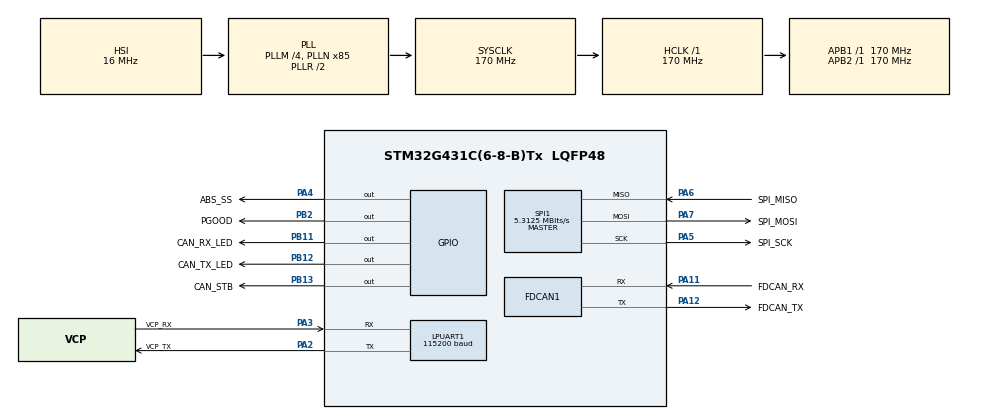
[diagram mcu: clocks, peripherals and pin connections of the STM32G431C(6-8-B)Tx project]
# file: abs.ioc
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Dma.LPUART1_TX.0.Direction=DMA_MEMORY_TO_PERIPH
Dma.LPUART1_TX.0.EventEnable=DISABLE
Dma.LPUART1_TX.0.Instance=DMA1_Channel1
Dma.LPUART1_TX.0.MemDataAlignment=DMA_MDATAALIGN_BYTE
Dma.LPUART1_TX.0.MemInc=DMA_MINC_ENABLE
Dma.LPUART1_TX.0.Mode=DMA_NORMAL
Dma.LPUART1_TX.0.PeriphDataAlignment=DMA_PDATAALIGN_BYTE
Dma.LPUART1_TX.0.PeriphInc=DMA_PINC_DISABLE
Dma.LPUART1_TX.0.Polarity=HAL_DMAMUX_REQ_GEN_RISING
Dma.LPUART1_TX.0.Priority=DMA_PRIORITY_LOW
Dma.LPUART1_TX.0.RequestNumber=1
Dma.LPUART1_TX.0.SignalID=NONE
Dma.LPUART1_TX.0.SyncEnable=DISABLE
Dma.LPUART1_TX.0.SyncPolarity=HAL_DMAMUX_SYNC_NO_EVENT
Dma.LPUART1_TX.0.SyncRequestNumber=1
Dma.LPUART1_TX.0.SyncSignalID=NONE
Dma.Request0=LPUART1_TX
Dma.Request1=SPI1_RX
Dma.Request2=SPI1_TX
Dma.SPI1_RX.1.Direction=DMA_PERIPH_TO_MEMORY
Dma.SPI1_RX.1.EventEnable=DISABLE
Dma.SPI1_RX.1.Instance=DMA1_Channel2
Dma.SPI1_RX.1.MemDataAlignment=DMA_MDATAALIGN_HALFWORD
Dma.SPI1_RX.1.MemInc=DMA_MINC_ENABLE
Dma.SPI1_RX.1.Mode=DMA_NORMAL
Dma.SPI1_RX.1.PeriphDataAlignment=DMA_PDATAALIGN_HALFWORD
Dma.SPI1_RX.1.PeriphInc=DMA_PINC_DISABLE
Dma.SPI1_RX.1.Polarity=HAL_DMAMUX_REQ_GEN_RISING
Dma.SPI1_RX.1.Priority=DMA_PRIORITY_LOW
Dma.SPI1_RX.1.RequestNumber=1
Dma.SPI1_RX.1.SignalID=NONE
Dma.SPI1_RX.1.SyncEnable=DISABLE
Dma.SPI1_RX.1.SyncPolarity=HAL_DMAMUX_SYNC_NO_EVENT
Dma.SPI1_RX.1.SyncRequestNumber=1
Dma.SPI1_RX.1.SyncSignalID=NONE
Dma.SPI1_TX.2.Direction=DMA_MEMORY_TO_PERIPH
Dma.SPI1_TX.2.EventEnable=DISABLE
Dma.SPI1_TX.2.Instance=DMA1_Channel3
Dma.SPI1_TX.2.MemDataAlignment=DMA_MDATAALIGN_HALFWORD
Dma.SPI1_TX.2.MemInc=DMA_MINC_ENABLE
Dma.SPI1_TX.2.Mode=DMA_NORMAL
Dma.SPI1_TX.2.PeriphDataAlignment=DMA_PDATAALIGN_HALFWORD
Dma.SPI1_TX.2.PeriphInc=DMA_PINC_DISABLE
Dma.SPI1_TX.2.Polarity=HAL_DMAMUX_REQ_GEN_RISING
Dma.SPI1_TX.2.Priority=DMA_PRIORITY_LOW
Dma.SPI1_TX.2.RequestNumber=1
Dma.SPI1_TX.2.SignalID=NONE
Dma.SPI1_TX.2.SyncEnable=DISABLE
Dma.SPI1_TX.2.SyncPolarity=HAL_DMAMUX_SYNC_NO_EVENT
Dma.SPI1_TX.2.SyncRequestNumber=1
Dma.SPI1_TX.2.SyncSignalID=NONE
FDCAN1.AutoRetransmission=ENABLE
FDCAN1.CalculateBaudRateNominal=999999
FDCAN1.CalculateTimeBitNominal=1000
FDCAN1.CalculateTimeQuantumNominal=11.764705882352942
FDCAN1.ClockDivider=FDCAN_CLOCK_DIV2
FDCAN1.DataSyncJumpWidth=5
FDCAN1.DataTimeSeg1=11
FDCAN1.DataTimeSeg2=5
FDCAN1.ExtFiltersNbr=3
FDCAN1.FrameFormat=FDCAN_FRAME_FD_BRS
FDCAN1.NominalPrescaler=1
FDCAN1.NominalSyncJumpWidth=16
FDCAN1.NominalTimeSeg1=56
FDCAN1.NominalTimeSeg2=28
LPUART1.BaudRate=115200
Mcu.Family=STM32G4
Mcu.Name=STM32G431C(6-8-B)Tx
Mcu.Package=LQFP48
NVIC.DMA1_Channel1_IRQn=true\:0\:0\:false\:false\:true\:false\:true\:true
NVIC.DMA1_Channel2_IRQn=true\:0\:0\:false\:false\:true\:false\:true\:true
NVIC.DMA1_Channel3_IRQn=true\:0\:0\:false\:false\:true\:false\:true\:true
NVIC.FDCAN1_IT0_IRQn=true\:0\:0\:false\:false\:true\:true\:true\:true
NVIC.FDCAN1_IT1_IRQn=true\:0\:0\:false\:false\:true\:true\:true\:true
NVIC.LPUART1_IRQn=true\:0\:0\:false\:false\:true\:true\:true\:true
NVIC.PriorityGroup=NVIC_PRIORITYGROUP_4
NVIC.SPI1_IRQn=true\:0\:0\:false\:false\:true\:true\:true\:true
NVIC.TIM1_TRG_COM_TIM17_IRQn=true\:0\:0\:false\:false\:true\:true\:true\:true
NVIC.TIM1_UP_TIM16_IRQn=true\:0\:0\:false\:false\:true\:true\:true\:true
PA11.GPIO_Label=FDCAN_RX
PA11.Mode=FDCAN_Activate
PA11.Signal=FDCAN1_RX
PA12.GPIO_Label=FDCAN_TX
PA12.Mode=FDCAN_Activate
PA12.Signal=FDCAN1_TX
PA13.GPIO_Label=SWDIO
PA13.Mode=Trace_Asynchronous_SW
PA13.Signal=SYS_JTMS-SWDIO
PA14.GPIO_Label=SWCLK
PA14.Mode=Trace_Asynchronous_SW
PA14.Signal=SYS_JTCK-SWCLK
PA2.GPIO_Label=VCP_TX
PA2.Mode=Asynchronous
PA2.Signal=LPUART1_TX
PA3.GPIO_Label=VCP_RX
PA3.Mode=Asynchronous
PA3.Signal=LPUART1_RX
PA4.GPIO_Label=ABS_SS
PA4.Signal=GPIO_Output
PA5.GPIO_Label=SPI_SCK
PA5.Mode=Full_Duplex_Master
PA5.Signal=SPI1_SCK
PA6.GPIO_Label=SPI_MISO
PA6.Mode=Full_Duplex_Master
PA6.Signal=SPI1_MISO
PA7.GPIO_Label=SPI_MOSI
PA7.Mode=Full_Duplex_Master
PA7.Signal=SPI1_MOSI
PB11.GPIO_Label=CAN_RX_LED
PB11.Signal=GPIO_Output
PB12.GPIO_Label=CAN_TX_LED
PB12.Signal=GPIO_Output
PB13.GPIO_Label=CAN_STB
PB13.Signal=GPIO_Output
PB2.GPIO_Label=PGOOD
PB2.Signal=GPIO_Output
PB3.GPIO_Label=SWO
PB3.Mode=Trace_Asynchronous_SW
PB3.Signal=SYS_JTDO-SWO
ProjectManager.HeapSize=0x200
ProjectManager.StackSize=0x400
ProjectManager.TargetToolchain=CMake
RCC.ADC12Freq_Value=170000000
RCC.AHBFreq_Value=170000000
RCC.APB1Freq_Value=170000000
RCC.APB1TimFreq_Value=170000000
RCC.APB2Freq_Value=170000000
RCC.APB2TimFreq_Value=170000000
RCC.CortexFreq_Value=170000000
RCC.EXTERNAL_CLOCK_VALUE=12288000
RCC.HCLKFreq_Value=170000000
RCC.HSE_VALUE=8000000
RCC.HSI48_VALUE=48000000
RCC.HSI_VALUE=16000000
RCC.LSE_VALUE=32768
RCC.PLLM=RCC_PLLM_DIV4
RCC.PLLN=85
RCC.SYSCLKFreq_VALUE=170000000
RCC.SYSCLKSource=RCC_SYSCLKSOURCE_PLLCLK
RCC.USBFreq_Value=170000000
RCC.VCOOutputFreq_Value=340000000
SPI1.BaudRatePrescaler=SPI_BAUDRATEPRESCALER_32
SPI1.CLKPhase=SPI_PHASE_2EDGE
SPI1.CRCCalculation=SPI_CRCCALCULATION_DISABLE
SPI1.CalculateBaudRate=5.3125 MBits/s
SPI1.DataSize=SPI_DATASIZE_16BIT
SPI1.Direction=SPI_DIRECTION_2LINES
SPI1.Mode=SPI_MODE_MASTER
SPI1.VirtualType=VM_MASTER
TIM16.PeriodNoDither=3333
TIM16.Prescaler=1699
TIM17.PeriodNoDither=3333
TIM17.Prescaler=1699
VP_SYS_VS_DBSignals.Mode=DisableDeadBatterySignals
VP_TIM16_VS_ClockSourceINT.Mode=Enable_Timer
VP_TIM17_VS_ClockSourceINT.Mode=Enable_Timer
board=custom

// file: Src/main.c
/* USER CODE BEGIN Header */
/**
  ******************************************************************************
  * @file           : main.c
  * @brief          : Main program body
  ******************************************************************************
  * @attention
  *
  * Copyright (c) 2026 STMicroelectronics.
  * All rights reserved.
  *
  * This software is licensed under terms that can be found in the LICENSE file
  * in the root directory of this software component.
  * If no LICENSE file comes with this software, it is provided AS-IS.
  *
  ******************************************************************************
  */
/* USER CODE END Header */
#include "main.h"

FDCAN_HandleTypeDef hfdcan1;

UART_HandleTypeDef hlpuart1;
DMA_HandleTypeDef hdma_lpuart1_tx;

SPI_HandleTypeDef hspi1;
DMA_HandleTypeDef hdma_spi1_rx;
DMA_HandleTypeDef hdma_spi1_tx;

TIM_HandleTypeDef htim16;
TIM_HandleTypeDef htim17;

void SystemClock_Config(void);
static void MX_GPIO_Init(void);
static void MX_DMA_Init(void);
static void MX_LPUART1_UART_Init(void);
static void MX_FDCAN1_Init(void);
static void MX_SPI1_Init(void);
static void MX_TIM16_Init(void);
static void MX_TIM17_Init(void);

int main(void)
{

  /* MCU Configuration--------------------------------------------------------*/

  /* Reset of all peripherals, Initializes the Flash interface and the Systick. */
  HAL_Init();

  /* Configure the system clock */
  SystemClock_Config();

  /* Initialize all configured peripherals */
  MX_GPIO_Init();
  MX_DMA_Init();
  MX_LPUART1_UART_Init();
  MX_FDCAN1_Init();
  MX_SPI1_Init();
  MX_TIM16_Init();
  MX_TIM17_Init();
  /* USER CODE BEGIN 2 */
  Init();
  /* USER CODE END 2 */

  /* Infinite loop */
  /* USER CODE BEGIN WHILE */
  Loop();
    /* USER CODE END WHILE */

}

void SystemClock_Config(void)
{
  RCC_OscInitTypeDef RCC_OscInitStruct = {0};
  RCC_ClkInitTypeDef RCC_ClkInitStruct = {0};

  /** Configure the main internal regulator output voltage
  */
  HAL_PWREx_ControlVoltageScaling(PWR_REGULATOR_VOLTAGE_SCALE1_BOOST);

  /** Initializes the RCC Oscillators according to the specified parameters
  * in the RCC_OscInitTypeDef structure.
  */
  RCC_OscInitStruct.OscillatorType = RCC_OSCILLATORTYPE_HSI;
  RCC_OscInitStruct.HSIState = RCC_HSI_ON;
  RCC_OscInitStruct.HSICalibrationValue = RCC_HSICALIBRATION_DEFAULT;
  RCC_OscInitStruct.PLL.PLLState = RCC_PLL_ON;
  RCC_OscInitStruct.PLL.PLLSource = RCC_PLLSOURCE_HSI;
  RCC_OscInitStruct.PLL.PLLM = RCC_PLLM_DIV4;
  RCC_OscInitStruct.PLL.PLLN = 85;
  RCC_OscInitStruct.PLL.PLLP = RCC_PLLP_DIV2;
  RCC_OscInitStruct.PLL.PLLQ = RCC_PLLQ_DIV2;
  RCC_OscInitStruct.PLL.PLLR = RCC_PLLR_DIV2;
  if (HAL_RCC_OscConfig(&RCC_OscInitStruct) != HAL_OK)
  {
    Error_Handler();
  }

  /** Initializes the CPU, AHB and APB buses clocks
  */
  RCC_ClkInitStruct.ClockType = RCC_CLOCKTYPE_HCLK|RCC_CLOCKTYPE_SYSCLK
                              |RCC_CLOCKTYPE_PCLK1|RCC_CLOCKTYPE_PCLK2;
  RCC_ClkInitStruct.SYSCLKSource = RCC_SYSCLKSOURCE_PLLCLK;
  RCC_ClkInitStruct.AHBCLKDivider = RCC_SYSCLK_DIV1;
  RCC_ClkInitStruct.APB1CLKDivider = RCC_HCLK_DIV1;
  RCC_ClkInitStruct.APB2CLKDivider = RCC_HCLK_DIV1;

  if (HAL_RCC_ClockConfig(&RCC_ClkInitStruct, FLASH_LATENCY_4) != HAL_OK)
  {
    Error_Handler();
  }
}

static void MX_FDCAN1_Init(void)
{

  hfdcan1.Instance = FDCAN1;
  hfdcan1.Init.ClockDivider = FDCAN_CLOCK_DIV2;
  hfdcan1.Init.FrameFormat = FDCAN_FRAME_FD_BRS;
  hfdcan1.Init.Mode = FDCAN_MODE_NORMAL;
  hfdcan1.Init.AutoRetransmission = ENABLE;
  hfdcan1.Init.TransmitPause = DISABLE;
  hfdcan1.Init.ProtocolException = DISABLE;
  hfdcan1.Init.NominalPrescaler = 1;
  hfdcan1.Init.NominalSyncJumpWidth = 16;
  hfdcan1.Init.NominalTimeSeg1 = 56;
  hfdcan1.Init.NominalTimeSeg2 = 28;
  hfdcan1.Init.DataPrescaler = 1;
  hfdcan1.Init.DataSyncJumpWidth = 5;
  hfdcan1.Init.DataTimeSeg1 = 11;
  hfdcan1.Init.DataTimeSeg2 = 5;
  hfdcan1.Init.StdFiltersNbr = 0;
  hfdcan1.Init.ExtFiltersNbr = 3;
  hfdcan1.Init.TxFifoQueueMode = FDCAN_TX_FIFO_OPERATION;
  if (HAL_FDCAN_Init(&hfdcan1) != HAL_OK)
  {
    Error_Handler();
  }

}

static void MX_LPUART1_UART_Init(void)
{

  hlpuart1.Instance = LPUART1;
  hlpuart1.Init.BaudRate = 115200;
  hlpuart1.Init.WordLength = UART_WORDLENGTH_8B;
  hlpuart1.Init.StopBits = UART_STOPBITS_1;
  hlpuart1.Init.Parity = UART_PARITY_NONE;
  hlpuart1.Init.Mode = UART_MODE_TX_RX;
  hlpuart1.Init.HwFlowCtl = UART_HWCONTROL_NONE;
  hlpuart1.Init.OneBitSampling = UART_ONE_BIT_SAMPLE_DISABLE;
  hlpuart1.Init.ClockPrescaler = UART_PRESCALER_DIV1;
  hlpuart1.AdvancedInit.AdvFeatureInit = UART_ADVFEATURE_NO_INIT;
  if (HAL_UART_Init(&hlpuart1) != HAL_OK)
  {
    Error_Handler();
  }
  if (HAL_UARTEx_SetTxFifoThreshold(&hlpuart1, UART_TXFIFO_THRESHOLD_1_8) != HAL_OK)
  {
    Error_Handler();
  }
  if (HAL_UARTEx_SetRxFifoThreshold(&hlpuart1, UART_RXFIFO_THRESHOLD_1_8) != HAL_OK)
  {
    Error_Handler();
  }
  if (HAL_UARTEx_DisableFifoMode(&hlpuart1) != HAL_OK)
  {
    Error_Handler();
  }

}

static void MX_SPI1_Init(void)
{

  /* SPI1 parameter configuration*/
  hspi1.Instance = SPI1;
  hspi1.Init.Mode = SPI_MODE_MASTER;
  hspi1.Init.Direction = SPI_DIRECTION_2LINES;
  hspi1.Init.DataSize = SPI_DATASIZE_16BIT;
  hspi1.Init.CLKPolarity = SPI_POLARITY_LOW;
  hspi1.Init.CLKPhase = SPI_PHASE_2EDGE;
  hspi1.Init.NSS = SPI_NSS_SOFT;
  hspi1.Init.BaudRatePrescaler = SPI_BAUDRATEPRESCALER_32;
  hspi1.Init.FirstBit = SPI_FIRSTBIT_MSB;
  hspi1.Init.TIMode = SPI_TIMODE_DISABLE;
  hspi1.Init.CRCCalculation = SPI_CRCCALCULATION_DISABLE;
  hspi1.Init.CRCPolynomial = 7;
  hspi1.Init.CRCLength = SPI_CRC_LENGTH_DATASIZE;
  hspi1.Init.NSSPMode = SPI_NSS_PULSE_DISABLE;
  if (HAL_SPI_Init(&hspi1) != HAL_OK)
  {
    Error_Handler();
  }

}

static void MX_TIM16_Init(void)
{

  htim16.Instance = TIM16;
  htim16.Init.Prescaler = 1699;
  htim16.Init.CounterMode = TIM_COUNTERMODE_UP;
  htim16.Init.Period = 3333;
  htim16.Init.ClockDivision = TIM_CLOCKDIVISION_DIV1;
  htim16.Init.RepetitionCounter = 0;
  htim16.Init.AutoReloadPreload = TIM_AUTORELOAD_PRELOAD_DISABLE;
  if (HAL_TIM_Base_Init(&htim16) != HAL_OK)
  {
    Error_Handler();
  }

}

static void MX_TIM17_Init(void)
{

  htim17.Instance = TIM17;
  htim17.Init.Prescaler = 1699;
  htim17.Init.CounterMode = TIM_COUNTERMODE_UP;
  htim17.Init.Period = 3333;
  htim17.Init.ClockDivision = TIM_CLOCKDIVISION_DIV1;
  htim17.Init.RepetitionCounter = 0;
  htim17.Init.AutoReloadPreload = TIM_AUTORELOAD_PRELOAD_DISABLE;
  if (HAL_TIM_Base_Init(&htim17) != HAL_OK)
  {
    Error_Handler();
  }

}

static void MX_DMA_Init(void)
{

  /* DMA controller clock enable */
  __HAL_RCC_DMAMUX1_CLK_ENABLE();
  __HAL_RCC_DMA1_CLK_ENABLE();

  /* DMA interrupt init */
  /* DMA1_Channel1_IRQn interrupt configuration */
  HAL_NVIC_SetPriority(DMA1_Channel1_IRQn, 0, 0);
  HAL_NVIC_EnableIRQ(DMA1_Channel1_IRQn);
  /* DMA1_Channel2_IRQn interrupt configuration */
  HAL_NVIC_SetPriority(DMA1_Channel2_IRQn, 0, 0);
  HAL_NVIC_EnableIRQ(DMA1_Channel2_IRQn);
  /* DMA1_Channel3_IRQn interrupt configuration */
  HAL_NVIC_SetPriority(DMA1_Channel3_IRQn, 0, 0);
  HAL_NVIC_EnableIRQ(DMA1_Channel3_IRQn);

}

static void MX_GPIO_Init(void)
{
  GPIO_InitTypeDef GPIO_InitStruct = {0};

  /* GPIO Ports Clock Enable */
  __HAL_RCC_GPIOA_CLK_ENABLE();
  __HAL_RCC_GPIOB_CLK_ENABLE();

  /*Configure GPIO pin Output Level */
  HAL_GPIO_WritePin(ABS_SS_GPIO_Port, ABS_SS_Pin, GPIO_PIN_RESET);

  /*Configure GPIO pin Output Level */
  HAL_GPIO_WritePin(GPIOB, PGOOD_Pin|CAN_RX_LED_Pin|CAN_TX_LED_Pin|CAN_STB_Pin, GPIO_PIN_RESET);

  /*Configure GPIO pin : ABS_SS_Pin */
  GPIO_InitStruct.Pin = ABS_SS_Pin;
  GPIO_InitStruct.Mode = GPIO_MODE_OUTPUT_PP;
  GPIO_InitStruct.Pull = GPIO_NOPULL;
  GPIO_InitStruct.Speed = GPIO_SPEED_FREQ_LOW;
  HAL_GPIO_Init(ABS_SS_GPIO_Port, &GPIO_InitStruct);

  /*Configure GPIO pins : PGOOD_Pin CAN_RX_LED_Pin CAN_TX_LED_Pin CAN_STB_Pin */
  GPIO_InitStruct.Pin = PGOOD_Pin|CAN_RX_LED_Pin|CAN_TX_LED_Pin|CAN_STB_Pin;
  GPIO_InitStruct.Mode = GPIO_MODE_OUTPUT_PP;
  GPIO_InitStruct.Pull = GPIO_NOPULL;
  GPIO_InitStruct.Speed = GPIO_SPEED_FREQ_LOW;
  HAL_GPIO_Init(GPIOB, &GPIO_InitStruct);

}

void Error_Handler(void)
{
  /* USER CODE BEGIN Error_Handler_Debug */
  Error();
  /* USER CODE END Error_Handler_Debug */
}
